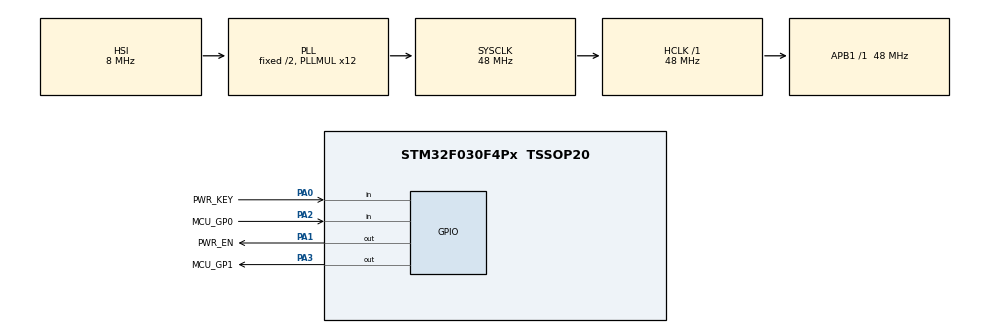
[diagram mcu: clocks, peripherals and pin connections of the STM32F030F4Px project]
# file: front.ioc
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Mcu.Family=STM32F0
Mcu.Name=STM32F030F4Px
Mcu.Package=TSSOP20
PA0.GPIO_Label=PWR_KEY
PA0.Signal=GPIO_Input
PA1.GPIO_Label=PWR_EN
PA1.Signal=GPIO_Output
PA13.Mode=Serial_Wire
PA13.Signal=SYS_SWDIO
PA14.Mode=Serial_Wire
PA14.Signal=SYS_SWCLK
PA2.GPIO_Label=MCU_GP0
PA2.Signal=GPIO_Input
PA3.GPIO_Label=MCU_GP1
PA3.Signal=GPIO_Output
ProjectManager.HeapSize=0x200
ProjectManager.StackSize=0x400
ProjectManager.TargetToolchain=STM32CubeIDE
RCC.AHBFreq_Value=48000000
RCC.APB1Freq_Value=48000000
RCC.APB1TimFreq_Value=48000000
RCC.HCLKFreq_Value=48000000
RCC.PLLMUL=RCC_PLL_MUL12
RCC.SYSCLKFreq_VALUE=48000000
RCC.SYSCLKSource=RCC_SYSCLKSOURCE_PLLCLK
VP_RTC_VS_RTC_Activate.Mode=RTC_Enabled
board=custom

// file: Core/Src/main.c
/* USER CODE BEGIN Header */
/**
  ******************************************************************************
  * @file           : main.c
  * @brief          : Main program body
  ******************************************************************************
  * @attention
  *
  * Copyright (c) 2026 STMicroelectronics.
  * All rights reserved.
  *
  * This software is licensed under terms that can be found in the LICENSE file
  * in the root directory of this software component.
  * If no LICENSE file comes with this software, it is provided AS-IS.
  *
  ******************************************************************************
  */
/* USER CODE END Header */
#include "main.h"

RTC_HandleTypeDef hrtc;

void SystemClock_Config(void);
static void MX_GPIO_Init(void);
static void MX_RTC_Init(void);

int main(void)
{

  /* MCU Configuration--------------------------------------------------------*/

  /* Reset of all peripherals, Initializes the Flash interface and the Systick. */
  HAL_Init();

  /* Configure the system clock */
  SystemClock_Config();

  /* Initialize all configured peripherals */
  MX_GPIO_Init();
  MX_RTC_Init();
  /* USER CODE BEGIN 2 */
  HAL_GPIO_WritePin(PWR_EN_GPIO_Port, PWR_EN_Pin, GPIO_PIN_SET);
  /* USER CODE END 2 */

  /* Infinite loop */
  while (1)
  {

  }
}

void SystemClock_Config(void)
{
  RCC_OscInitTypeDef RCC_OscInitStruct = {0};
  RCC_ClkInitTypeDef RCC_ClkInitStruct = {0};
  RCC_PeriphCLKInitTypeDef PeriphClkInit = {0};

  /** Initializes the RCC Oscillators according to the specified parameters
  * in the RCC_OscInitTypeDef structure.
  */
  RCC_OscInitStruct.OscillatorType = RCC_OSCILLATORTYPE_HSI|RCC_OSCILLATORTYPE_LSI;
  RCC_OscInitStruct.HSIState = RCC_HSI_ON;
  RCC_OscInitStruct.HSICalibrationValue = RCC_HSICALIBRATION_DEFAULT;
  RCC_OscInitStruct.LSIState = RCC_LSI_ON;
  RCC_OscInitStruct.PLL.PLLState = RCC_PLL_ON;
  RCC_OscInitStruct.PLL.PLLSource = RCC_PLLSOURCE_HSI;
  RCC_OscInitStruct.PLL.PLLMUL = RCC_PLL_MUL12;
  RCC_OscInitStruct.PLL.PREDIV = RCC_PREDIV_DIV1;
  if (HAL_RCC_OscConfig(&RCC_OscInitStruct) != HAL_OK)
  {
    Error_Handler();
  }

  /** Initializes the CPU, AHB and APB buses clocks
  */
  RCC_ClkInitStruct.ClockType = RCC_CLOCKTYPE_HCLK|RCC_CLOCKTYPE_SYSCLK
                              |RCC_CLOCKTYPE_PCLK1;
  RCC_ClkInitStruct.SYSCLKSource = RCC_SYSCLKSOURCE_PLLCLK;
  RCC_ClkInitStruct.AHBCLKDivider = RCC_SYSCLK_DIV1;
  RCC_ClkInitStruct.APB1CLKDivider = RCC_HCLK_DIV1;

  if (HAL_RCC_ClockConfig(&RCC_ClkInitStruct, FLASH_LATENCY_1) != HAL_OK)
  {
    Error_Handler();
  }
  PeriphClkInit.PeriphClockSelection = RCC_PERIPHCLK_RTC;
  PeriphClkInit.RTCClockSelection = RCC_RTCCLKSOURCE_LSI;
  if (HAL_RCCEx_PeriphCLKConfig(&PeriphClkInit) != HAL_OK)
  {
    Error_Handler();
  }
}

static void MX_RTC_Init(void)
{

  /** Initialize RTC Only
  */
  hrtc.Instance = RTC;
  hrtc.Init.HourFormat = RTC_HOURFORMAT_24;
  hrtc.Init.AsynchPrediv = 127;
  hrtc.Init.SynchPrediv = 255;
  hrtc.Init.OutPut = RTC_OUTPUT_DISABLE;
  hrtc.Init.OutPutPolarity = RTC_OUTPUT_POLARITY_HIGH;
  hrtc.Init.OutPutType = RTC_OUTPUT_TYPE_OPENDRAIN;
  if (HAL_RTC_Init(&hrtc) != HAL_OK)
  {
    Error_Handler();
  }

}

static void MX_GPIO_Init(void)
{
  GPIO_InitTypeDef GPIO_InitStruct = {0};

  /* GPIO Ports Clock Enable */
  __HAL_RCC_GPIOA_CLK_ENABLE();

  /*Configure GPIO pin Output Level */
  HAL_GPIO_WritePin(GPIOA, PWR_EN_Pin|MCU_GP1_Pin, GPIO_PIN_RESET);

  /*Configure GPIO pins : PWR_KEY_Pin MCU_GP0_Pin */
  GPIO_InitStruct.Pin = PWR_KEY_Pin|MCU_GP0_Pin;
  GPIO_InitStruct.Mode = GPIO_MODE_INPUT;
  GPIO_InitStruct.Pull = GPIO_NOPULL;
  HAL_GPIO_Init(GPIOA, &GPIO_InitStruct);

  /*Configure GPIO pins : PWR_EN_Pin MCU_GP1_Pin */
  GPIO_InitStruct.Pin = PWR_EN_Pin|MCU_GP1_Pin;
  GPIO_InitStruct.Mode = GPIO_MODE_OUTPUT_PP;
  GPIO_InitStruct.Pull = GPIO_NOPULL;
  GPIO_InitStruct.Speed = GPIO_SPEED_FREQ_LOW;
  HAL_GPIO_Init(GPIOA, &GPIO_InitStruct);

}

void Error_Handler(void)
{
  __disable_irq();
  while (1)
  {
  }
}
